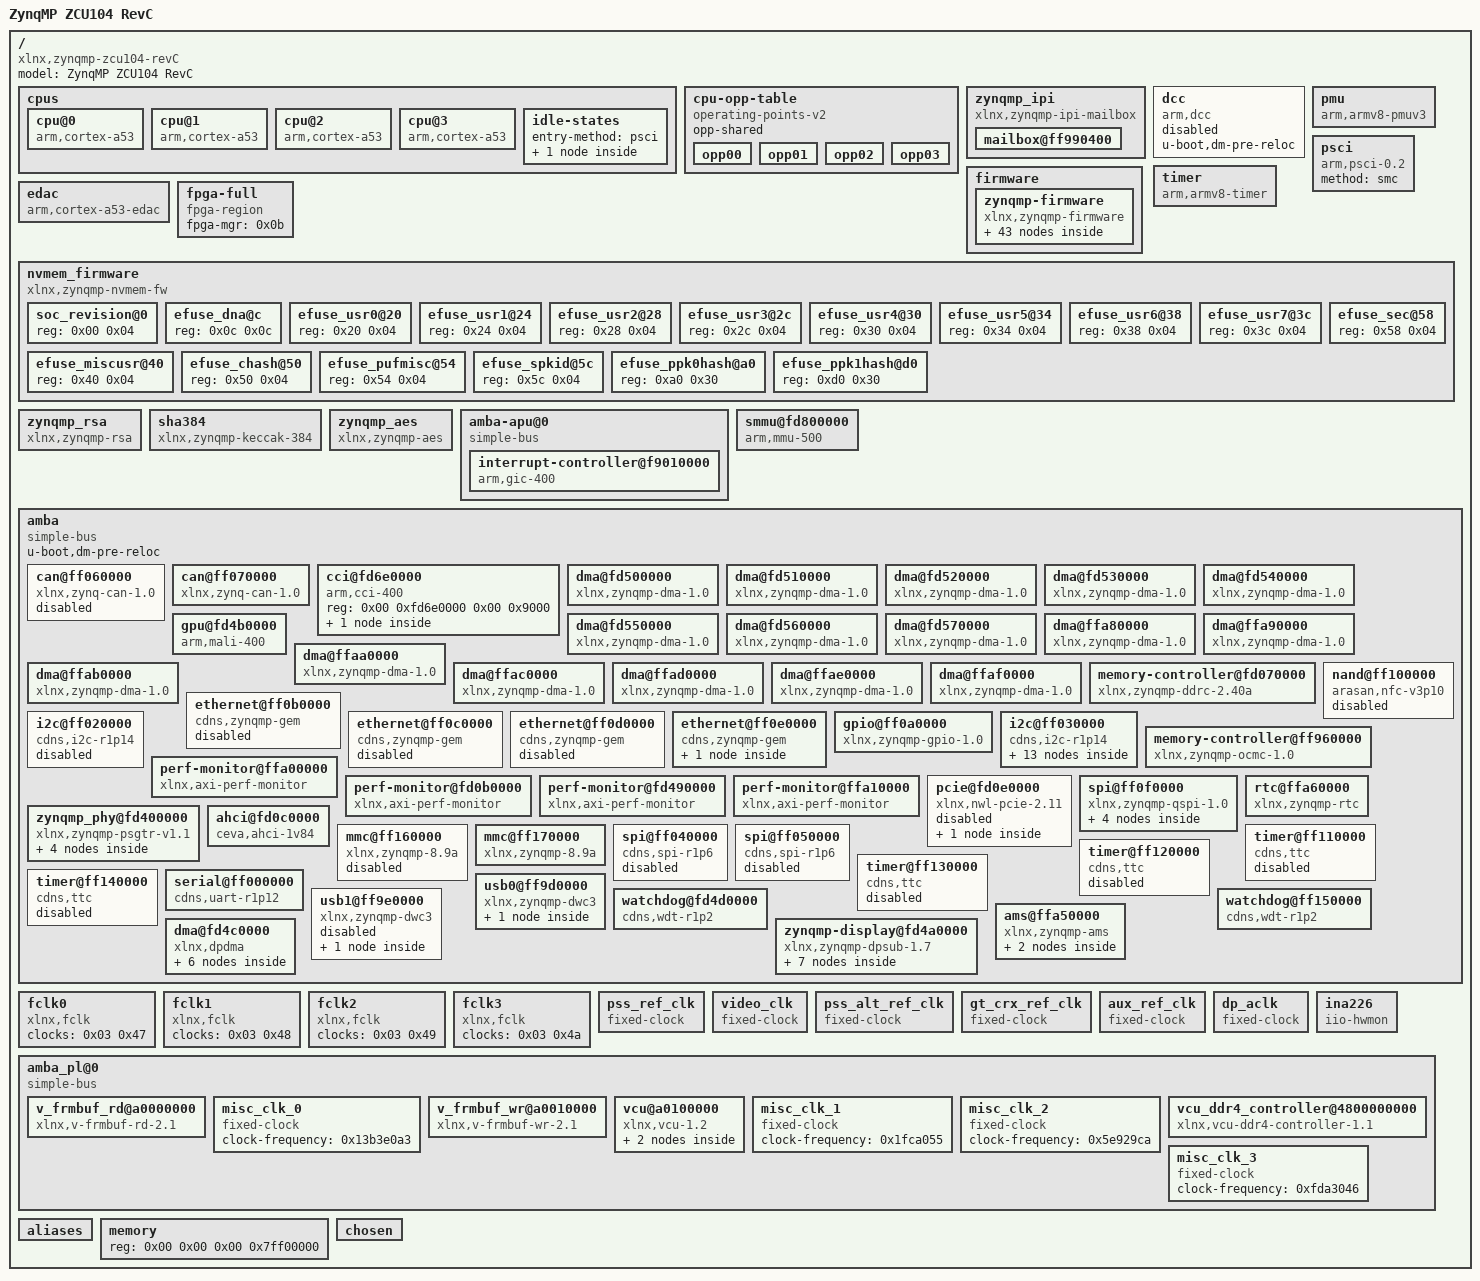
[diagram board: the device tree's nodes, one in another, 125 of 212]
/dts-v1/;

/ {
	compatible = "xlnx,zynqmp-zcu104-revC\0xlnx,zynqmp-zcu104\0xlnx,zynqmp";
	#address-cells = <0x02>;
	#size-cells = <0x02>;
	model = "ZynqMP ZCU104 RevC";

	cpus {
		#address-cells = <0x01>;
		#size-cells = <0x00>;

		cpu@0 {
			compatible = "arm,cortex-a53";
			device_type = "cpu";
			enable-method = "psci";
			operating-points-v2 = <0x01>;
			reg = <0x00>;
			cpu-idle-states = <0x02>;
			clocks = <0x03 0x0a>;
		};

		cpu@1 {
			compatible = "arm,cortex-a53";
			device_type = "cpu";
			enable-method = "psci";
			reg = <0x01>;
			operating-points-v2 = <0x01>;
			cpu-idle-states = <0x02>;
		};

		cpu@2 {
			compatible = "arm,cortex-a53";
			device_type = "cpu";
			enable-method = "psci";
			reg = <0x02>;
			operating-points-v2 = <0x01>;
			cpu-idle-states = <0x02>;
		};

		cpu@3 {
			compatible = "arm,cortex-a53";
			device_type = "cpu";
			enable-method = "psci";
			reg = <0x03>;
			operating-points-v2 = <0x01>;
			cpu-idle-states = <0x02>;
		};

		idle-states {
			entry-method = "psci";

			cpu-sleep-0 {
				compatible = "arm,idle-state";
				arm,psci-suspend-param = <0x40000000>;
				local-timer-stop;
				entry-latency-us = <0x12c>;
				exit-latency-us = <0x258>;
				min-residency-us = <0x2710>;
				phandle = <0x02>;
			};
		};
	};

	cpu-opp-table {
		compatible = "operating-points-v2";
		opp-shared;
		phandle = <0x01>;

		opp00 {
			opp-hz = <0x00 0x47868bf4>;
			opp-microvolt = <0xf4240>;
			clock-latency-ns = <0x7a120>;
		};

		opp01 {
			opp-hz = <0x00 0x23c345fa>;
			opp-microvolt = <0xf4240>;
			clock-latency-ns = <0x7a120>;
		};

		opp02 {
			opp-hz = <0x00 0x17d783fc>;
			opp-microvolt = <0xf4240>;
			clock-latency-ns = <0x7a120>;
		};

		opp03 {
			opp-hz = <0x00 0x11e1a2fd>;
			opp-microvolt = <0xf4240>;
			clock-latency-ns = <0x7a120>;
		};
	};

	zynqmp_ipi {
		u-boot,dm-pre-reloc;
		compatible = "xlnx,zynqmp-ipi-mailbox";
		interrupt-parent = <0x04>;
		interrupts = <0x00 0x23 0x04>;
		xlnx,ipi-id = <0x00>;
		#address-cells = <0x02>;
		#size-cells = <0x02>;
		ranges;

		mailbox@ff990400 {
			u-boot,dm-pre-reloc;
			reg = <0x00 0xff9905c0 0x00 0x20 0x00 0xff9905e0 0x00 0x20 0x00 0xff990e80 0x00 0x20 0x00 0xff990ea0 0x00 0x20>;
			reg-names = "local_request_region\0local_response_region\0remote_request_region\0remote_response_region";
			#mbox-cells = <0x01>;
			xlnx,ipi-id = <0x04>;
			phandle = <0x05>;
		};
	};

	dcc {
		compatible = "arm,dcc";
		status = "disabled";
		u-boot,dm-pre-reloc;
	};

	pmu {
		compatible = "arm,armv8-pmuv3";
		interrupt-parent = <0x04>;
		interrupts = <0x00 0x8f 0x04 0x00 0x90 0x04 0x00 0x91 0x04 0x00 0x92 0x04>;
	};

	psci {
		compatible = "arm,psci-0.2";
		method = "smc";
	};

	firmware {

		zynqmp-firmware {
			compatible = "xlnx,zynqmp-firmware";
			u-boot,dm-pre-reloc;
			method = "smc";
			#power-domain-cells = <0x01>;
			phandle = <0x26>;

			pcap {
				compatible = "xlnx,zynqmp-pcap-fpga";
				clock-names = "ref_clk";
				clocks = <0x03 0x29>;
				phandle = <0x0b>;
			};

			zynqmp-power {
				u-boot,dm-pre-reloc;
				compatible = "xlnx,zynqmp-power";
				interrupt-parent = <0x04>;
				interrupts = <0x00 0x23 0x04>;
				mboxes = <0x05 0x00 0x05 0x01>;
				mbox-names = "tx\0rx";
			};

			reset-controller {
				compatible = "xlnx,zynqmp-reset";
				#reset-cells = <0x01>;
				phandle = <0x31>;
			};

			pinctrl {
				compatible = "xlnx,zynqmp-pinctrl";
				status = "okay";

				can1-default {
					phandle = <0x27>;

					mux {
						function = "can1";
						groups = "can1_6_grp";
					};

					conf {
						groups = "can1_6_grp";
						slew-rate = <0x01>;
						io-standard = <0x01>;
						drive-strength = <0x0c>;
					};

					conf-rx {
						pins = "MIO25";
						bias-high-impedance;
					};

					conf-tx {
						pins = "MIO24";
						bias-disable;
					};
				};

				i2c1-default {
					phandle = <0x2b>;

					mux {
						groups = "i2c1_4_grp";
						function = "i2c1";
					};

					conf {
						groups = "i2c1_4_grp";
						bias-pull-up;
						slew-rate = <0x01>;
						io-standard = <0x01>;
						drive-strength = <0x0c>;
					};
				};

				i2c1-gpio {
					phandle = <0x2c>;

					mux {
						groups = "gpio0_16_grp\0gpio0_17_grp";
						function = "gpio0";
					};

					conf {
						groups = "gpio0_16_grp\0gpio0_17_grp";
						slew-rate = <0x01>;
						io-standard = <0x01>;
						drive-strength = <0x0c>;
					};
				};

				gem3-default {
					phandle = <0x2a>;

					mux {
						function = "ethernet3";
						groups = "ethernet3_0_grp";
					};

					conf {
						groups = "ethernet3_0_grp";
						slew-rate = <0x01>;
						io-standard = <0x01>;
						drive-strength = <0x0c>;
					};

					conf-rx {
						pins = "MIO70\0MIO71\0MIO72\0MIO73\0MIO74\0MIO75";
						bias-high-impedance;
						low-power-disable;
					};

					conf-tx {
						pins = "MIO64\0MIO65\0MIO66\0MIO67\0MIO68\0MIO69";
						bias-disable;
						low-power-enable;
					};

					mux-mdio {
						function = "mdio3";
						groups = "mdio3_0_grp";
					};

					conf-mdio {
						groups = "mdio3_0_grp";
						slew-rate = <0x01>;
						io-standard = <0x01>;
						bias-disable;
					};
				};

				sdhci1-default {
					phandle = <0x33>;

					mux {
						groups = "sdio1_0_grp";
						function = "sdio1";
					};

					conf {
						groups = "sdio1_0_grp";
						slew-rate = <0x01>;
						io-standard = <0x01>;
						bias-disable;
						drive-strength = <0x0c>;
					};

					mux-cd {
						groups = "sdio1_cd_0_grp";
						function = "sdio1_cd";
					};

					conf-cd {
						groups = "sdio1_cd_0_grp";
						bias-high-impedance;
						bias-pull-up;
						slew-rate = <0x01>;
						io-standard = <0x01>;
					};
				};

				uart0-default {
					phandle = <0x34>;

					mux {
						groups = "uart0_4_grp";
						function = "uart0";
					};

					conf {
						groups = "uart0_4_grp";
						slew-rate = <0x01>;
						io-standard = <0x01>;
						drive-strength = <0x0c>;
					};

					conf-rx {
						pins = "MIO18";
						bias-high-impedance;
					};

					conf-tx {
						pins = "MIO19";
						bias-disable;
					};
				};

				uart1-default {
					phandle = <0x35>;

					mux {
						groups = "uart1_5_grp";
						function = "uart1";
					};

					conf {
						groups = "uart1_5_grp";
						slew-rate = <0x01>;
						io-standard = <0x01>;
						drive-strength = <0x0c>;
					};

					conf-rx {
						pins = "MIO21";
						bias-high-impedance;
					};

					conf-tx {
						pins = "MIO20";
						bias-disable;
					};
				};

				usb0-default {
					phandle = <0x36>;

					mux {
						groups = "usb0_0_grp";
						function = "usb0";
					};

					conf {
						groups = "usb0_0_grp";
						slew-rate = <0x01>;
						io-standard = <0x01>;
						drive-strength = <0x0c>;
					};

					conf-rx {
						pins = "MIO52\0MIO53\0MIO55";
						bias-high-impedance;
					};

					conf-tx {
						pins = "MIO54\0MIO56\0MIO57\0MIO58\0MIO59\0MIO60\0MIO61\0MIO62\0MIO63";
						bias-disable;
					};
				};
			};

			clock-controller {
				u-boot,dm-pre-reloc;
				#clock-cells = <0x01>;
				compatible = "xlnx,zynqmp-clk";
				clocks = <0x06 0x07 0x08 0x09 0x0a>;
				clock-names = "pss_ref_clk\0video_clk\0pss_alt_ref_clk\0aux_ref_clk\0gt_crx_ref_clk";
				phandle = <0x03>;
			};
		};
	};

	timer {
		compatible = "arm,armv8-timer";
		interrupt-parent = <0x04>;
		interrupts = <0x01 0x0d 0xf08 0x01 0x0e 0xf08 0x01 0x0b 0xf08 0x01 0x0a 0xf08>;
	};

	edac {
		compatible = "arm,cortex-a53-edac";
	};

	fpga-full {
		compatible = "fpga-region";
		fpga-mgr = <0x0b>;
		#address-cells = <0x02>;
		#size-cells = <0x02>;
		ranges;
	};

	nvmem_firmware {
		compatible = "xlnx,zynqmp-nvmem-fw";
		#address-cells = <0x01>;
		#size-cells = <0x01>;

		soc_revision@0 {
			reg = <0x00 0x04>;
			phandle = <0x30>;
		};

		efuse_dna@c {
			reg = <0x0c 0x0c>;
		};

		efuse_usr0@20 {
			reg = <0x20 0x04>;
		};

		efuse_usr1@24 {
			reg = <0x24 0x04>;
		};

		efuse_usr2@28 {
			reg = <0x28 0x04>;
		};

		efuse_usr3@2c {
			reg = <0x2c 0x04>;
		};

		efuse_usr4@30 {
			reg = <0x30 0x04>;
		};

		efuse_usr5@34 {
			reg = <0x34 0x04>;
		};

		efuse_usr6@38 {
			reg = <0x38 0x04>;
		};

		efuse_usr7@3c {
			reg = <0x3c 0x04>;
		};

		efuse_miscusr@40 {
			reg = <0x40 0x04>;
		};

		efuse_chash@50 {
			reg = <0x50 0x04>;
		};

		efuse_pufmisc@54 {
			reg = <0x54 0x04>;
		};

		efuse_sec@58 {
			reg = <0x58 0x04>;
		};

		efuse_spkid@5c {
			reg = <0x5c 0x04>;
		};

		efuse_ppk0hash@a0 {
			reg = <0xa0 0x30>;
		};

		efuse_ppk1hash@d0 {
			reg = <0xd0 0x30>;
		};
	};

	zynqmp_rsa {
		compatible = "xlnx,zynqmp-rsa";
	};

	sha384 {
		compatible = "xlnx,zynqmp-keccak-384";
	};

	zynqmp_aes {
		compatible = "xlnx,zynqmp-aes";
	};

	amba-apu@0 {
		compatible = "simple-bus";
		#address-cells = <0x02>;
		#size-cells = <0x01>;
		ranges = <0x00 0x00 0x00 0x00 0xffffffff>;

		interrupt-controller@f9010000 {
			compatible = "arm,gic-400";
			#interrupt-cells = <0x03>;
			reg = <0x00 0xf9010000 0x10000 0x00 0xf9020000 0x20000 0x00 0xf9040000 0x20000 0x00 0xf9060000 0x20000>;
			interrupt-controller;
			interrupt-parent = <0x04>;
			interrupts = <0x01 0x09 0xf04>;
			num_cpus = <0x02>;
			num_interrupts = <0x60>;
			phandle = <0x04>;
		};
	};

	smmu@fd800000 {
		compatible = "arm,mmu-500";
		reg = <0x00 0xfd800000 0x00 0x20000>;
		#iommu-cells = <0x01>;
		status = "okay";
		#global-interrupts = <0x01>;
		interrupt-parent = <0x04>;
		interrupts = <0x00 0x9b 0x04 0x00 0x9b 0x04 0x00 0x9b 0x04 0x00 0x9b 0x04 0x00 0x9b 0x04 0x00 0x9b 0x04 0x00 0x9b 0x04 0x00 0x9b 0x04 0x00 0x9b 0x04 0x00 0x9b 0x04 0x00 0x9b 0x04 0x00 0x9b 0x04 0x00 0x9b 0x04 0x00 0x9b 0x04 0x00 0x9b 0x04 0x00 0x9b 0x04 0x00 0x9b 0x04>;
		mmu-masters = <0x0c 0x874 0x0d 0x875 0x0e 0x876 0x0f 0x877 0x10 0x860 0x11 0x861 0x12 0x873 0x13 0x868 0x14 0x869 0x15 0x86a 0x16 0x86b 0x17 0x86c 0x18 0x86d 0x19 0x86e 0x1a 0x86f 0x1b 0x14e8 0x1c 0x14e9 0x1d 0x14ea 0x1e 0x14eb 0x1f 0x14ec 0x20 0x14ed 0x21 0x14ee 0x22 0x14ef 0x23 0x870 0x24 0x871 0x25 0x872>;
		phandle = <0x28>;
	};

	amba {
		compatible = "simple-bus";
		u-boot,dm-pre-reloc;
		#address-cells = <0x02>;
		#size-cells = <0x02>;
		ranges;

		can@ff060000 {
			compatible = "xlnx,zynq-can-1.0";
			status = "disabled";
			clock-names = "can_clk\0pclk";
			reg = <0x00 0xff060000 0x00 0x1000>;
			interrupts = <0x00 0x17 0x04>;
			interrupt-parent = <0x04>;
			tx-fifo-depth = <0x40>;
			rx-fifo-depth = <0x40>;
			power-domains = <0x26 0x2f>;
			clocks = <0x03 0x3f 0x03 0x1f>;
		};

		can@ff070000 {
			compatible = "xlnx,zynq-can-1.0";
			status = "okay";
			clock-names = "can_clk\0pclk";
			reg = <0x00 0xff070000 0x00 0x1000>;
			interrupts = <0x00 0x18 0x04>;
			interrupt-parent = <0x04>;
			tx-fifo-depth = <0x40>;
			rx-fifo-depth = <0x40>;
			power-domains = <0x26 0x30>;
			clocks = <0x03 0x40 0x03 0x1f>;
			pinctrl-names = "default";
			pinctrl-0 = <0x27>;
		};

		cci@fd6e0000 {
			compatible = "arm,cci-400";
			reg = <0x00 0xfd6e0000 0x00 0x9000>;
			ranges = <0x00 0x00 0xfd6e0000 0x10000>;
			#address-cells = <0x01>;
			#size-cells = <0x01>;

			pmu@9000 {
				compatible = "arm,cci-400-pmu,r1";
				reg = <0x9000 0x5000>;
				interrupt-parent = <0x04>;
				interrupts = <0x00 0x7b 0x04 0x00 0x7b 0x04 0x00 0x7b 0x04 0x00 0x7b 0x04 0x00 0x7b 0x04>;
			};
		};

		dma@fd500000 {
			status = "okay";
			compatible = "xlnx,zynqmp-dma-1.0";
			reg = <0x00 0xfd500000 0x00 0x1000>;
			interrupt-parent = <0x04>;
			interrupts = <0x00 0x7c 0x04>;
			clock-names = "clk_main\0clk_apb";
			xlnx,bus-width = <0x80>;
			#stream-id-cells = <0x01>;
			iommus = <0x28 0x14e8>;
			power-domains = <0x26 0x2a>;
			clocks = <0x03 0x13 0x03 0x1f>;
			phandle = <0x1b>;
		};

		dma@fd510000 {
			status = "okay";
			compatible = "xlnx,zynqmp-dma-1.0";
			reg = <0x00 0xfd510000 0x00 0x1000>;
			interrupt-parent = <0x04>;
			interrupts = <0x00 0x7d 0x04>;
			clock-names = "clk_main\0clk_apb";
			xlnx,bus-width = <0x80>;
			#stream-id-cells = <0x01>;
			iommus = <0x28 0x14e9>;
			power-domains = <0x26 0x2a>;
			clocks = <0x03 0x13 0x03 0x1f>;
			phandle = <0x1c>;
		};

		dma@fd520000 {
			status = "okay";
			compatible = "xlnx,zynqmp-dma-1.0";
			reg = <0x00 0xfd520000 0x00 0x1000>;
			interrupt-parent = <0x04>;
			interrupts = <0x00 0x7e 0x04>;
			clock-names = "clk_main\0clk_apb";
			xlnx,bus-width = <0x80>;
			#stream-id-cells = <0x01>;
			iommus = <0x28 0x14ea>;
			power-domains = <0x26 0x2a>;
			clocks = <0x03 0x13 0x03 0x1f>;
			phandle = <0x1d>;
		};

		dma@fd530000 {
			status = "okay";
			compatible = "xlnx,zynqmp-dma-1.0";
			reg = <0x00 0xfd530000 0x00 0x1000>;
			interrupt-parent = <0x04>;
			interrupts = <0x00 0x7f 0x04>;
			clock-names = "clk_main\0clk_apb";
			xlnx,bus-width = <0x80>;
			#stream-id-cells = <0x01>;
			iommus = <0x28 0x14eb>;
			power-domains = <0x26 0x2a>;
			clocks = <0x03 0x13 0x03 0x1f>;
			phandle = <0x1e>;
		};

		dma@fd540000 {
			status = "okay";
			compatible = "xlnx,zynqmp-dma-1.0";
			reg = <0x00 0xfd540000 0x00 0x1000>;
			interrupt-parent = <0x04>;
			interrupts = <0x00 0x80 0x04>;
			clock-names = "clk_main\0clk_apb";
			xlnx,bus-width = <0x80>;
			#stream-id-cells = <0x01>;
			iommus = <0x28 0x14ec>;
			power-domains = <0x26 0x2a>;
			clocks = <0x03 0x13 0x03 0x1f>;
			phandle = <0x1f>;
		};

		dma@fd550000 {
			status = "okay";
			compatible = "xlnx,zynqmp-dma-1.0";
			reg = <0x00 0xfd550000 0x00 0x1000>;
			interrupt-parent = <0x04>;
			interrupts = <0x00 0x81 0x04>;
			clock-names = "clk_main\0clk_apb";
			xlnx,bus-width = <0x80>;
			#stream-id-cells = <0x01>;
			iommus = <0x28 0x14ed>;
			power-domains = <0x26 0x2a>;
			clocks = <0x03 0x13 0x03 0x1f>;
			phandle = <0x20>;
		};

		dma@fd560000 {
			status = "okay";
			compatible = "xlnx,zynqmp-dma-1.0";
			reg = <0x00 0xfd560000 0x00 0x1000>;
			interrupt-parent = <0x04>;
			interrupts = <0x00 0x82 0x04>;
			clock-names = "clk_main\0clk_apb";
			xlnx,bus-width = <0x80>;
			#stream-id-cells = <0x01>;
			iommus = <0x28 0x14ee>;
			power-domains = <0x26 0x2a>;
			clocks = <0x03 0x13 0x03 0x1f>;
			phandle = <0x21>;
		};

		dma@fd570000 {
			status = "okay";
			compatible = "xlnx,zynqmp-dma-1.0";
			reg = <0x00 0xfd570000 0x00 0x1000>;
			interrupt-parent = <0x04>;
			interrupts = <0x00 0x83 0x04>;
			clock-names = "clk_main\0clk_apb";
			xlnx,bus-width = <0x80>;
			#stream-id-cells = <0x01>;
			iommus = <0x28 0x14ef>;
			power-domains = <0x26 0x2a>;
			clocks = <0x03 0x13 0x03 0x1f>;
			phandle = <0x22>;
		};

		gpu@fd4b0000 {
			status = "okay";
			compatible = "arm,mali-400\0arm,mali-utgard";
			reg = <0x00 0xfd4b0000 0x00 0x10000>;
			interrupt-parent = <0x04>;
			interrupts = <0x00 0x84 0x04 0x00 0x84 0x04 0x00 0x84 0x04 0x00 0x84 0x04 0x00 0x84 0x04 0x00 0x84 0x04>;
			interrupt-names = "IRQGP\0IRQGPMMU\0IRQPP0\0IRQPPMMU0\0IRQPP1\0IRQPPMMU1";
			clock-names = "gpu\0gpu_pp0\0gpu_pp1";
			power-domains = <0x26 0x3a>;
			clocks = <0x03 0x18 0x03 0x19 0x03 0x1a>;
			xlnx,tz-nonsecure = <0x01>;
		};

		dma@ffa80000 {
			status = "okay";
			compatible = "xlnx,zynqmp-dma-1.0";
			reg = <0x00 0xffa80000 0x00 0x1000>;
			interrupt-parent = <0x04>;
			interrupts = <0x00 0x4d 0x04>;
			clock-names = "clk_main\0clk_apb";
			xlnx,bus-width = <0x40>;
			#stream-id-cells = <0x01>;
			power-domains = <0x26 0x2b>;
			clocks = <0x03 0x44 0x03 0x1f>;
			phandle = <0x13>;
		};

		dma@ffa90000 {
			status = "okay";
			compatible = "xlnx,zynqmp-dma-1.0";
			reg = <0x00 0xffa90000 0x00 0x1000>;
			interrupt-parent = <0x04>;
			interrupts = <0x00 0x4e 0x04>;
			clock-names = "clk_main\0clk_apb";
			xlnx,bus-width = <0x40>;
			#stream-id-cells = <0x01>;
			power-domains = <0x26 0x2b>;
			clocks = <0x03 0x44 0x03 0x1f>;
			phandle = <0x14>;
		};

		dma@ffaa0000 {
			status = "okay";
			compatible = "xlnx,zynqmp-dma-1.0";
			reg = <0x00 0xffaa0000 0x00 0x1000>;
			interrupt-parent = <0x04>;
			interrupts = <0x00 0x4f 0x04>;
			clock-names = "clk_main\0clk_apb";
			xlnx,bus-width = <0x40>;
			#stream-id-cells = <0x01>;
			power-domains = <0x26 0x2b>;
			clocks = <0x03 0x44 0x03 0x1f>;
			phandle = <0x15>;
		};

		dma@ffab0000 {
			status = "okay";
			compatible = "xlnx,zynqmp-dma-1.0";
			reg = <0x00 0xffab0000 0x00 0x1000>;
			interrupt-parent = <0x04>;
			interrupts = <0x00 0x50 0x04>;
			clock-names = "clk_main\0clk_apb";
			xlnx,bus-width = <0x40>;
			#stream-id-cells = <0x01>;
			power-domains = <0x26 0x2b>;
			clocks = <0x03 0x44 0x03 0x1f>;
			phandle = <0x16>;
		};

		dma@ffac0000 {
			status = "okay";
			compatible = "xlnx,zynqmp-dma-1.0";
			reg = <0x00 0xffac0000 0x00 0x1000>;
			interrupt-parent = <0x04>;
			interrupts = <0x00 0x51 0x04>;
			clock-names = "clk_main\0clk_apb";
			xlnx,bus-width = <0x40>;
			#stream-id-cells = <0x01>;
			power-domains = <0x26 0x2b>;
			clocks = <0x03 0x44 0x03 0x1f>;
			phandle = <0x17>;
		};

		dma@ffad0000 {
			status = "okay";
			compatible = "xlnx,zynqmp-dma-1.0";
			reg = <0x00 0xffad0000 0x00 0x1000>;
			interrupt-parent = <0x04>;
			interrupts = <0x00 0x52 0x04>;
			clock-names = "clk_main\0clk_apb";
			xlnx,bus-width = <0x40>;
			#stream-id-cells = <0x01>;
			power-domains = <0x26 0x2b>;
			clocks = <0x03 0x44 0x03 0x1f>;
			phandle = <0x18>;
		};

		dma@ffae0000 {
			status = "okay";
			compatible = "xlnx,zynqmp-dma-1.0";
			reg = <0x00 0xffae0000 0x00 0x1000>;
			interrupt-parent = <0x04>;
			interrupts = <0x00 0x53 0x04>;
			clock-names = "clk_main\0clk_apb";
			xlnx,bus-width = <0x40>;
			#stream-id-cells = <0x01>;
			power-domains = <0x26 0x2b>;
			clocks = <0x03 0x44 0x03 0x1f>;
			phandle = <0x19>;
		};

		dma@ffaf0000 {
			status = "okay";
			compatible = "xlnx,zynqmp-dma-1.0";
			reg = <0x00 0xffaf0000 0x00 0x1000>;
			interrupt-parent = <0x04>;
			interrupts = <0x00 0x54 0x04>;
			clock-names = "clk_main\0clk_apb";
			xlnx,bus-width = <0x40>;
			#stream-id-cells = <0x01>;
			power-domains = <0x26 0x2b>;
			clocks = <0x03 0x44 0x03 0x1f>;
			phandle = <0x1a>;
		};

		memory-controller@fd070000 {
			compatible = "xlnx,zynqmp-ddrc-2.40a";
			reg = <0x00 0xfd070000 0x00 0x30000>;
			interrupt-parent = <0x04>;
			interrupts = <0x00 0x70 0x04>;
		};

		nand@ff100000 {
			compatible = "arasan,nfc-v3p10";
			status = "disabled";
			reg = <0x00 0xff100000 0x00 0x1000>;
			clock-names = "clk_sys\0clk_flash";
			interrupt-parent = <0x04>;
			interrupts = <0x00 0x0e 0x04>;
			#address-cells = <0x01>;
			#size-cells = <0x00>;
			#stream-id-cells = <0x01>;
			iommus = <0x28 0x872>;
			power-domains = <0x26 0x2c>;
			clocks = <0x03 0x3c 0x03 0x1f>;
			phandle = <0x25>;
		};

		ethernet@ff0b0000 {
			compatible = "cdns,zynqmp-gem\0cdns,gem";
			status = "disabled";
			interrupt-parent = <0x04>;
			interrupts = <0x00 0x39 0x04 0x00 0x39 0x04>;
			reg = <0x00 0xff0b0000 0x00 0x1000>;
			clock-names = "pclk\0hclk\0tx_clk\0rx_clk\0tsu_clk";
			#address-cells = <0x01>;
			#size-cells = <0x00>;
			#stream-id-cells = <0x01>;
			iommus = <0x28 0x874>;
			power-domains = <0x26 0x1d>;
			clocks = <0x03 0x1f 0x03 0x68 0x03 0x2d 0x03 0x31 0x03 0x2c>;
			phandle = <0x0c>;
		};

		ethernet@ff0c0000 {
			compatible = "cdns,zynqmp-gem\0cdns,gem";
			status = "disabled";
			interrupt-parent = <0x04>;
			interrupts = <0x00 0x3b 0x04 0x00 0x3b 0x04>;
			reg = <0x00 0xff0c0000 0x00 0x1000>;
			clock-names = "pclk\0hclk\0tx_clk\0rx_clk\0tsu_clk";
			#address-cells = <0x01>;
			#size-cells = <0x00>;
			#stream-id-cells = <0x01>;
			iommus = <0x28 0x875>;
			power-domains = <0x26 0x1e>;
			clocks = <0x03 0x1f 0x03 0x69 0x03 0x2e 0x03 0x32 0x03 0x2c>;
			phandle = <0x0d>;
		};

		ethernet@ff0d0000 {
			compatible = "cdns,zynqmp-gem\0cdns,gem";
			status = "disabled";
			interrupt-parent = <0x04>;
			interrupts = <0x00 0x3d 0x04 0x00 0x3d 0x04>;
			reg = <0x00 0xff0d0000 0x00 0x1000>;
			clock-names = "pclk\0hclk\0tx_clk\0rx_clk\0tsu_clk";
			#address-cells = <0x01>;
			#size-cells = <0x00>;
			#stream-id-cells = <0x01>;
			iommus = <0x28 0x876>;
			power-domains = <0x26 0x1f>;
			clocks = <0x03 0x1f 0x03 0x6a 0x03 0x2f 0x03 0x33 0x03 0x2c>;
			phandle = <0x0e>;
		};

		ethernet@ff0e0000 {
			compatible = "cdns,zynqmp-gem\0cdns,gem";
			status = "okay";
			interrupt-parent = <0x04>;
			interrupts = <0x00 0x3f 0x04 0x00 0x3f 0x04>;
			reg = <0x00 0xff0e0000 0x00 0x1000>;
			clock-names = "pclk\0hclk\0tx_clk\0rx_clk\0tsu_clk";
			#address-cells = <0x01>;
			#size-cells = <0x00>;
			#stream-id-cells = <0x01>;
			iommus = <0x28 0x877>;
			power-domains = <0x26 0x20>;
			clocks = <0x03 0x1f 0x03 0x6b 0x03 0x30 0x03 0x34 0x03 0x2c>;
			phy-handle = <0x29>;
			pinctrl-names = "default";
			pinctrl-0 = <0x2a>;
			phy-mode = "rgmii-id";
			xlnx,ptp-enet-clock = <0x00>;
			local-mac-address = [00 0a 35 00 22 01];
			phandle = <0x0f>;

			ethernet-phy@c {
				reg = <0x0c>;
				ti,rx-internal-delay = <0x08>;
				ti,tx-internal-delay = <0x0a>;
				ti,fifo-depth = <0x01>;
				ti,dp83867-rxctrl-strap-quirk;
				phandle = <0x29>;
			};
		};

		gpio@ff0a0000 {
			compatible = "xlnx,zynqmp-gpio-1.0";
			status = "okay";
			#gpio-cells = <0x02>;
			gpio-controller;
			interrupt-parent = <0x04>;
			interrupts = <0x00 0x10 0x04>;
			interrupt-controller;
			#interrupt-cells = <0x02>;
			reg = <0x00 0xff0a0000 0x00 0x1000>;
			power-domains = <0x26 0x2e>;
			clocks = <0x03 0x1f>;
			emio-gpio-width = <0x20>;
			gpio-mask-high = <0x00>;
			gpio-mask-low = <0x5600>;
			phandle = <0x2d>;
		};

		i2c@ff020000 {
			compatible = "cdns,i2c-r1p14\0cdns,i2c-r1p10";
			status = "disabled";
			interrupt-parent = <0x04>;
			interrupts = <0x00 0x11 0x04>;
			reg = <0x00 0xff020000 0x00 0x1000>;
			#address-cells = <0x01>;
			#size-cells = <0x00>;
			power-domains = <0x26 0x25>;
			clocks = <0x03 0x3d>;
		};

		i2c@ff030000 {
			compatible = "cdns,i2c-r1p14\0cdns,i2c-r1p10";
			status = "okay";
			interrupt-parent = <0x04>;
			interrupts = <0x00 0x12 0x04>;
			reg = <0x00 0xff030000 0x00 0x1000>;
			#address-cells = <0x01>;
			#size-cells = <0x00>;
			power-domains = <0x26 0x26>;
			clocks = <0x03 0x3e>;
			pinctrl-names = "default\0gpio";
			pinctrl-0 = <0x2b>;
			pinctrl-1 = <0x2c>;
			scl-gpios = <0x2d 0x10 0x00>;
			sda-gpios = <0x2d 0x11 0x00>;
			clock-frequency = <0x61a80>;

			gpio@20 {
				compatible = "ti,tca6416";
				reg = <0x20>;
				gpio-controller;
				#gpio-cells = <0x02>;
			};

			i2c-mux@74 {
				compatible = "nxp,pca9548";
				#address-cells = <0x01>;
				#size-cells = <0x00>;
				reg = <0x74>;

				i2c@0 {
					#address-cells = <0x01>;
					#size-cells = <0x00>;
					reg = <0x00>;

					eeprom@54 {
						compatible = "atmel,24c08";
						reg = <0x54>;
						#address-cells = <0x01>;
						#size-cells = <0x01>;
					};
				};

				i2c@1 {
					#address-cells = <0x01>;
					#size-cells = <0x00>;
					reg = <0x01>;

					clock-generator@6c {
						compatible = "idt,8t49n287";
						reg = <0x6c>;
					};
				};

				i2c@2 {
					#address-cells = <0x01>;
					#size-cells = <0x00>;
					reg = <0x02>;

					irps5401@43 {
						compatible = "infineon,irps5401";
						reg = <0x43>;
					};

					irps5401@44 {
						compatible = "infineon,irps5401";
						reg = <0x44>;
					};
				};

				i2c@3 {
					#address-cells = <0x01>;
					#size-cells = <0x00>;
					reg = <0x03>;

					ina226@40 {
						compatible = "ti,ina226";
						#io-channel-cells = <0x01>;
						reg = <0x40>;
						shunt-resistor = <0x1388>;
						phandle = <0x3f>;
					};
				};

				i2c@5 {
					#address-cells = <0x01>;
					#size-cells = <0x00>;
					reg = <0x05>;
				};

				i2c@7 {
					#address-cells = <0x01>;
					#size-cells = <0x00>;
					reg = <0x07>;
				};
			};
		};

		memory-controller@ff960000 {
			compatible = "xlnx,zynqmp-ocmc-1.0";
			reg = <0x00 0xff960000 0x00 0x1000>;
			interrupt-parent = <0x04>;
			interrupts = <0x00 0x0a 0x04>;
		};

		perf-monitor@ffa00000 {
			compatible = "xlnx,axi-perf-monitor";
			reg = <0x00 0xffa00000 0x00 0x10000>;
			interrupts = <0x00 0x19 0x04>;
			interrupt-parent = <0x04>;
			xlnx,enable-profile = <0x00>;
			xlnx,enable-trace = <0x00>;
			xlnx,num-monitor-slots = <0x01>;
			xlnx,enable-event-count = <0x01>;
			xlnx,enable-event-log = <0x01>;
			xlnx,have-sampled-metric-cnt = <0x01>;
			xlnx,num-of-counters = <0x08>;
			xlnx,metric-count-width = <0x20>;
			xlnx,metrics-sample-count-width = <0x20>;
			xlnx,global-count-width = <0x20>;
			xlnx,metric-count-scale = <0x01>;
			clocks = <0x03 0x1f>;
		};

		perf-monitor@fd0b0000 {
			compatible = "xlnx,axi-perf-monitor";
			reg = <0x00 0xfd0b0000 0x00 0x10000>;
			interrupts = <0x00 0x7b 0x04>;
			interrupt-parent = <0x04>;
			xlnx,enable-profile = <0x00>;
			xlnx,enable-trace = <0x00>;
			xlnx,num-monitor-slots = <0x06>;
			xlnx,enable-event-count = <0x01>;
			xlnx,enable-event-log = <0x00>;
			xlnx,have-sampled-metric-cnt = <0x01>;
			xlnx,num-of-counters = <0x0a>;
			xlnx,metric-count-width = <0x20>;
			xlnx,metrics-sample-count-width = <0x20>;
			xlnx,global-count-width = <0x20>;
			xlnx,metric-count-scale = <0x01>;
			clocks = <0x03 0x1c>;
		};

		perf-monitor@fd490000 {
			compatible = "xlnx,axi-perf-monitor";
			reg = <0x00 0xfd490000 0x00 0x10000>;
			interrupts = <0x00 0x7b 0x04>;
			interrupt-parent = <0x04>;
			xlnx,enable-profile = <0x00>;
			xlnx,enable-trace = <0x00>;
			xlnx,num-monitor-slots = <0x01>;
			xlnx,enable-event-count = <0x01>;
			xlnx,enable-event-log = <0x00>;
			xlnx,have-sampled-metric-cnt = <0x01>;
			xlnx,num-of-counters = <0x08>;
			xlnx,metric-count-width = <0x20>;
			xlnx,metrics-sample-count-width = <0x20>;
			xlnx,global-count-width = <0x20>;
			xlnx,metric-count-scale = <0x01>;
			clocks = <0x03 0x1c>;
		};

		perf-monitor@ffa10000 {
			compatible = "xlnx,axi-perf-monitor";
			reg = <0x00 0xffa10000 0x00 0x10000>;
			interrupts = <0x00 0x19 0x04>;
			interrupt-parent = <0x04>;
			xlnx,enable-profile = <0x00>;
			xlnx,enable-trace = <0x00>;
			xlnx,num-monitor-slots = <0x01>;
			xlnx,enable-event-count = <0x01>;
			xlnx,enable-event-log = <0x01>;
			xlnx,have-sampled-metric-cnt = <0x01>;
			xlnx,num-of-counters = <0x08>;
			xlnx,metric-count-width = <0x20>;
			xlnx,metrics-sample-count-width = <0x20>;
			xlnx,global-count-width = <0x20>;
			xlnx,metric-count-scale = <0x01>;
			clocks = <0x03 0x1f>;
		};

		pcie@fd0e0000 {
			compatible = "xlnx,nwl-pcie-2.11";
			status = "disabled";
			#address-cells = <0x03>;
			#size-cells = <0x02>;
			#interrupt-cells = <0x01>;
			msi-controller;
			device_type = "pci";
			interrupt-parent = <0x04>;
			interrupts = <0x00 0x76 0x04 0x00 0x75 0x04 0x00 0x74 0x04 0x00 0x73 0x04 0x00 0x72 0x04>;
			interrupt-names = "misc\0dummy\0intx\0msi1\0msi0";
			msi-parent = <0x2e>;
			reg = <0x00 0xfd0e0000 0x00 0x1000 0x00 0xfd480000 0x00 0x1000 0x80 0x00 0x00 0x1000000>;
			reg-names = "breg\0pcireg\0cfg";
			ranges = <0x2000000 0x00 0xe0000000 0x00 0xe0000000 0x00 0x10000000 0x43000000 0x06 0x00 0x06 0x00 0x02 0x00>;
			interrupt-map-mask = <0x00 0x00 0x00 0x07>;
			bus-range = <0x00 0xff>;
			interrupt-map = <0x00 0x00 0x00 0x01 0x2f 0x01 0x00 0x00 0x00 0x02 0x2f 0x02 0x00 0x00 0x00 0x03 0x2f 0x03 0x00 0x00 0x00 0x04 0x2f 0x04>;
			power-domains = <0x26 0x3b>;
			clocks = <0x03 0x17>;
			phandle = <0x2e>;

			legacy-interrupt-controller {
				interrupt-controller;
				#address-cells = <0x00>;
				#interrupt-cells = <0x01>;
				phandle = <0x2f>;
			};
		};

		spi@ff0f0000 {
			u-boot,dm-pre-reloc;
			compatible = "xlnx,zynqmp-qspi-1.0";
			status = "okay";
			clock-names = "ref_clk\0pclk";
			interrupts = <0x00 0x0f 0x04>;
			interrupt-parent = <0x04>;
			num-cs = <0x01>;
			reg = <0x00 0xff0f0000 0x00 0x1000 0x00 0xc0000000 0x00 0x8000000>;
			#address-cells = <0x01>;
			#size-cells = <0x00>;
			#stream-id-cells = <0x01>;
			iommus = <0x28 0x873>;
			power-domains = <0x26 0x2d>;
			clocks = <0x03 0x35 0x03 0x1f>;
			is-dual = <0x00>;
			spi-rx-bus-width = <0x04>;
			spi-tx-bus-width = <0x04>;
			phandle = <0x12>;

			flash@0 {
				compatible = "m25p80\0jedec,spi-nor";
				#address-cells = <0x01>;
				#size-cells = <0x01>;
				reg = <0x00>;
				spi-tx-bus-width = <0x01>;
				spi-rx-bus-width = <0x04>;
				spi-max-frequency = <0x66ff300>;

				partition@0 {
					label = "boot";
					reg = <0x00 0x1e00000>;
				};

				partition@1 {
					label = "bootenv";
					reg = <0x1e00000 0x40000>;
				};

				partition@2 {
					label = "kernel";
					reg = <0x1e40000 0x21c0000>;
				};
			};
		};

		rtc@ffa60000 {
			compatible = "xlnx,zynqmp-rtc";
			status = "okay";
			reg = <0x00 0xffa60000 0x00 0x100>;
			interrupt-parent = <0x04>;
			interrupts = <0x00 0x1a 0x04 0x00 0x1b 0x04>;
			interrupt-names = "alarm\0sec";
			calibration = <0x8000>;
		};

		zynqmp_phy@fd400000 {
			compatible = "xlnx,zynqmp-psgtr-v1.1";
			status = "okay";
			reg = <0x00 0xfd400000 0x00 0x40000 0x00 0xfd3d0000 0x00 0x1000>;
			reg-names = "serdes\0siou";
			nvmem-cells = <0x30>;
			nvmem-cell-names = "soc_revision";
			resets = <0x31 0x10 0x31 0x3b 0x31 0x3c 0x31 0x3d 0x31 0x3e 0x31 0x3f 0x31 0x40 0x31 0x03 0x31 0x1d 0x31 0x1e 0x31 0x1f 0x31 0x20>;
			reset-names = "sata_rst\0usb0_crst\0usb1_crst\0usb0_hibrst\0usb1_hibrst\0usb0_apbrst\0usb1_apbrst\0dp_rst\0gem0_rst\0gem1_rst\0gem2_rst\0gem3_rst";

			lane0 {
				#phy-cells = <0x04>;
				phandle = <0x3a>;
			};

			lane1 {
				#phy-cells = <0x04>;
				phandle = <0x39>;
			};

			lane2 {
				#phy-cells = <0x04>;
				phandle = <0x37>;
			};

			lane3 {
				#phy-cells = <0x04>;
				phandle = <0x32>;
			};
		};

		ahci@fd0c0000 {
			compatible = "ceva,ahci-1v84";
			status = "okay";
			reg = <0x00 0xfd0c0000 0x00 0x2000>;
			interrupt-parent = <0x04>;
			interrupts = <0x00 0x85 0x04>;
			power-domains = <0x26 0x1c>;
			#stream-id-cells = <0x04>;
			clocks = <0x03 0x16>;
			ceva,p0-cominit-params = <0x18401828>;
			ceva,p0-comwake-params = <0x614080e>;
			ceva,p0-burst-params = <0x13084a06>;
			ceva,p0-retry-params = <0x96a43ffc>;
			ceva,p1-cominit-params = <0x18401828>;
			ceva,p1-comwake-params = <0x614080e>;
			ceva,p1-burst-params = <0x13084a06>;
			ceva,p1-retry-params = <0x96a43ffc>;
			phy-names = "sata-phy";
			phys = <0x32 0x01 0x01 0x01 0x7735940>;
			xlnx,tz-nonsecure-sata0 = <0x00>;
			xlnx,tz-nonsecure-sata1 = <0x00>;
		};

		mmc@ff160000 {
			u-boot,dm-pre-reloc;
			compatible = "xlnx,zynqmp-8.9a\0arasan,sdhci-8.9a";
			status = "disabled";
			interrupt-parent = <0x04>;
			interrupts = <0x00 0x30 0x04>;
			reg = <0x00 0xff160000 0x00 0x1000>;
			clock-names = "clk_xin\0clk_ahb";
			xlnx,device_id = <0x00>;
			#stream-id-cells = <0x01>;
			iommus = <0x28 0x870>;
			power-domains = <0x26 0x27>;
			nvmem-cells = <0x30>;
			nvmem-cell-names = "soc_revision";
			#clock-cells = <0x01>;
			clock-output-names = "clk_out_sd0\0clk_in_sd0";
			clocks = <0x03 0x36 0x03 0x1f>;
			phandle = <0x23>;
		};

		mmc@ff170000 {
			u-boot,dm-pre-reloc;
			compatible = "xlnx,zynqmp-8.9a\0arasan,sdhci-8.9a";
			status = "okay";
			interrupt-parent = <0x04>;
			interrupts = <0x00 0x31 0x04>;
			reg = <0x00 0xff170000 0x00 0x1000>;
			clock-names = "clk_xin\0clk_ahb";
			xlnx,device_id = <0x01>;
			#stream-id-cells = <0x01>;
			iommus = <0x28 0x871>;
			power-domains = <0x26 0x28>;
			nvmem-cells = <0x30>;
			nvmem-cell-names = "soc_revision";
			#clock-cells = <0x01>;
			clock-output-names = "clk_out_sd1\0clk_in_sd1";
			clocks = <0x03 0x37 0x03 0x1f>;	
			no-1-8-v;
			pinctrl-names = "default";
			pinctrl-0 = <0x33>;
			xlnx,mio_bank = <0x01>;
			disable-wp;
			clock-frequency = <0xb2d05e0>;
			phandle = <0x24>;
		};

		spi@ff040000 {
			compatible = "cdns,spi-r1p6";
			status = "disabled";
			interrupt-parent = <0x04>;
			interrupts = <0x00 0x13 0x04>;
			reg = <0x00 0xff040000 0x00 0x1000>;
			clock-names = "ref_clk\0pclk";
			#address-cells = <0x01>;
			#size-cells = <0x00>;
			power-domains = <0x26 0x23>;
			clocks = <0x03 0x3a 0x03 0x1f>;
		};

		spi@ff050000 {
			compatible = "cdns,spi-r1p6";
			status = "disabled";
			interrupt-parent = <0x04>;
			interrupts = <0x00 0x14 0x04>;
			reg = <0x00 0xff050000 0x00 0x1000>;
			clock-names = "ref_clk\0pclk";
			#address-cells = <0x01>;
			#size-cells = <0x00>;
			power-domains = <0x26 0x24>;
			clocks = <0x03 0x3b 0x03 0x1f>;
		};

		timer@ff110000 {
			compatible = "cdns,ttc";
			status = "disabled";
			interrupt-parent = <0x04>;
			interrupts = <0x00 0x24 0x04 0x00 0x25 0x04 0x00 0x26 0x04>;
			reg = <0x00 0xff110000 0x00 0x1000>;
			timer-width = <0x20>;
			power-domains = <0x26 0x18>;
			clocks = <0x03 0x1f>;
		};

		timer@ff120000 {
			compatible = "cdns,ttc";
			status = "disabled";
			interrupt-parent = <0x04>;
			interrupts = <0x00 0x27 0x04 0x00 0x28 0x04 0x00 0x29 0x04>;
			reg = <0x00 0xff120000 0x00 0x1000>;
			timer-width = <0x20>;
			power-domains = <0x26 0x19>;
			clocks = <0x03 0x1f>;
		};

		timer@ff130000 {
			compatible = "cdns,ttc";
			status = "disabled";
			interrupt-parent = <0x04>;
			interrupts = <0x00 0x2a 0x04 0x00 0x2b 0x04 0x00 0x2c 0x04>;
			reg = <0x00 0xff130000 0x00 0x1000>;
			timer-width = <0x20>;
			power-domains = <0x26 0x1a>;
			clocks = <0x03 0x1f>;
		};

		timer@ff140000 {
			compatible = "cdns,ttc";
			status = "disabled";
			interrupt-parent = <0x04>;
			interrupts = <0x00 0x2d 0x04 0x00 0x2e 0x04 0x00 0x2f 0x04>;
			reg = <0x00 0xff140000 0x00 0x1000>;
			timer-width = <0x20>;
			power-domains = <0x26 0x1b>;
			clocks = <0x03 0x1f>;
		};

		serial@ff000000 {
			u-boot,dm-pre-reloc;
			compatible = "cdns,uart-r1p12\0xlnx,xuartps";
			status = "okay";
			interrupt-parent = <0x04>;
			interrupts = <0x00 0x15 0x04>;
			reg = <0x00 0xff000000 0x00 0x1000>;
			clock-names = "uart_clk\0pclk";
			power-domains = <0x26 0x21>;
			clocks = <0x03 0x38 0x03 0x1f>;
			pinctrl-names = "default";
			pinctrl-0 = <0x34>;
			cts-override;
			device_type = "serial";
			port-number = <0x00>;
		};

		// serial@ff010000 {
		// 	u-boot,dm-pre-reloc;
		// 	compatible = "cdns,uart-r1p12\0xlnx,xuartps";
		// 	status = "okay";
		// 	interrupt-parent = <0x04>;
		// 	interrupts = <0x00 0x16 0x04>;
		// 	reg = <0x00 0xff010000 0x00 0x1000>;
		// 	clock-names = "uart_clk\0pclk";
		// 	power-domains = <0x26 0x22>;
		// 	clocks = <0x03 0x39 0x03 0x1f>;
		// 	pinctrl-names = "default";
		// 	pinctrl-0 = <0x35>;
		// 	cts-override;
		// 	device_type = "serial";
		// 	port-number = <0x01>;
		// };

		usb0@ff9d0000 {
			#address-cells = <0x02>;
			#size-cells = <0x02>;
			status = "okay";
			compatible = "xlnx,zynqmp-dwc3";
			reg = <0x00 0xff9d0000 0x00 0x100>;
			clock-names = "bus_clk\0ref_clk";
			power-domains = <0x26 0x16>;
			ranges;
			nvmem-cells = <0x30>;
			nvmem-cell-names = "soc_revision";
			clocks = <0x03 0x20 0x03 0x22>;
			pinctrl-names = "default";
			pinctrl-0 = <0x36>;
			xlnx,tz-nonsecure = <0x01>;
			xlnx,usb-polarity = <0x00>;
			xlnx,usb-reset-mode = <0x00>;

			dwc3@fe200000 {
				compatible = "snps,dwc3";
				status = "okay";
				reg = <0x00 0xfe200000 0x00 0x40000>;
				interrupt-parent = <0x04>;
				interrupt-names = "dwc_usb3\0otg\0hiber";
				interrupts = <0x00 0x41 0x04 0x00 0x45 0x04 0x00 0x4b 0x04>;
				#stream-id-cells = <0x01>;
				iommus = <0x28 0x860>;
				snps,quirk-frame-length-adjustment = <0x20>;
				snps,refclk_fladj;
				snps,enable_guctl1_resume_quirk;
				snps,enable_guctl1_ipd_quirk;
				snps,xhci-stream-quirk;
				dr_mode = "host";
				snps,usb3_lpm_capable;
				phy-names = "usb3-phy";
				phys = <0x37 0x04 0x00 0x02 0x18cba80>;
				maximum-speed = "super-speed";
				phandle = <0x10>;
			};
		};

		usb1@ff9e0000 {
			#address-cells = <0x02>;
			#size-cells = <0x02>;
			status = "disabled";
			compatible = "xlnx,zynqmp-dwc3";
			reg = <0x00 0xff9e0000 0x00 0x100>;
			clock-names = "bus_clk\0ref_clk";
			power-domains = <0x26 0x17>;
			ranges;
			nvmem-cells = <0x30>;
			nvmem-cell-names = "soc_revision";
			clocks = <0x03 0x21 0x03 0x22>;

			dwc3@fe300000 {
				compatible = "snps,dwc3";
				status = "disabled";
				reg = <0x00 0xfe300000 0x00 0x40000>;
				interrupt-parent = <0x04>;
				interrupt-names = "dwc_usb3\0otg\0hiber";
				interrupts = <0x00 0x46 0x04 0x00 0x4a 0x04 0x00 0x4c 0x04>;
				#stream-id-cells = <0x01>;
				iommus = <0x28 0x861>;
				snps,quirk-frame-length-adjustment = <0x20>;
				snps,refclk_fladj;
				snps,enable_guctl1_resume_quirk;
				snps,enable_guctl1_ipd_quirk;
				snps,xhci-stream-quirk;
				phandle = <0x11>;
			};
		};

		watchdog@fd4d0000 {
			compatible = "cdns,wdt-r1p2";
			status = "okay";
			interrupt-parent = <0x04>;
			interrupts = <0x00 0x71 0x01>;
			reg = <0x00 0xfd4d0000 0x00 0x1000>;
			timeout-sec = <0x3c>;
			reset-on-timeout;
			clocks = <0x03 0x4b>;
		};

		watchdog@ff150000 {
			compatible = "cdns,wdt-r1p2";
			status = "okay";
			interrupt-parent = <0x04>;
			interrupts = <0x00 0x34 0x01>;
			reg = <0x00 0xff150000 0x00 0x1000>;
			timeout-sec = <0x0a>;
			clocks = <0x03 0x70>;
		};

		ams@ffa50000 {
			compatible = "xlnx,zynqmp-ams";
			status = "okay";
			interrupt-parent = <0x04>;
			interrupts = <0x00 0x38 0x04>;
			interrupt-names = "ams-irq";
			reg = <0x00 0xffa50000 0x00 0x800>;
			reg-names = "ams-base";
			#address-cells = <0x02>;
			#size-cells = <0x02>;
			#io-channel-cells = <0x01>;
			ranges;
			clocks = <0x03 0x46>;

			ams_ps@ffa50800 {
				compatible = "xlnx,zynqmp-ams-ps";
				status = "okay";
				reg = <0x00 0xffa50800 0x00 0x400>;
			};

			ams_pl@ffa50c00 {
				compatible = "xlnx,zynqmp-ams-pl";
				status = "okay";
				reg = <0x00 0xffa50c00 0x00 0x400>;
			};
		};

		dma@fd4c0000 {
			compatible = "xlnx,dpdma";
			status = "okay";
			reg = <0x00 0xfd4c0000 0x00 0x1000>;
			interrupts = <0x00 0x7a 0x04>;
			interrupt-parent = <0x04>;
			clock-names = "axi_clk";
			power-domains = <0x26 0x29>;
			dma-channels = <0x06>;
			#dma-cells = <0x01>;
			clocks = <0x03 0x14>;
			phandle = <0x3b>;

			dma-video0channel {
				compatible = "xlnx,video0";
			};

			dma-video1channel {
				compatible = "xlnx,video1";
			};

			dma-video2channel {
				compatible = "xlnx,video2";
			};

			dma-graphicschannel {
				compatible = "xlnx,graphics";
			};

			dma-audio0channel {
				compatible = "xlnx,audio0";
			};

			dma-audio1channel {
				compatible = "xlnx,audio1";
			};
		};

		zynqmp-display@fd4a0000 {
			compatible = "xlnx,zynqmp-dpsub-1.7";
			status = "okay";
			reg = <0x00 0xfd4a0000 0x00 0x1000 0x00 0xfd4aa000 0x00 0x1000 0x00 0xfd4ab000 0x00 0x1000 0x00 0xfd4ac000 0x00 0x1000>;
			reg-names = "dp\0blend\0av_buf\0aud";
			interrupts = <0x00 0x77 0x04>;
			interrupt-parent = <0x04>;
			clock-names = "dp_apb_clk\0dp_aud_clk\0dp_vtc_pixel_clk_in";
			power-domains = <0x26 0x29>;
			clocks = <0x38 0x03 0x11 0x03 0x10>;
			phy-names = "dp-phy0\0dp-phy1";
			phys = <0x39 0x06 0x00 0x03 0x19bfcc0 0x3a 0x06 0x01 0x03 0x19bfcc0>;
			xlnx,max-lanes = <0x02>;

			vid-layer {
				dma-names = "vid0\0vid1\0vid2";
				dmas = <0x3b 0x00 0x3b 0x01 0x3b 0x02>;
			};

			gfx-layer {
				dma-names = "gfx0";
				dmas = <0x3b 0x03>;
			};

			i2c-bus {
			};

			zynqmp_dp_snd_codec0 {
				compatible = "xlnx,dp-snd-codec";
				clock-names = "aud_clk";
				clocks = <0x03 0x11>;
				status = "okay";
				phandle = <0x3e>;
			};

			zynqmp_dp_snd_pcm0 {
				compatible = "xlnx,dp-snd-pcm";
				dmas = <0x3b 0x04>;
				dma-names = "tx";
				status = "okay";
				phandle = <0x3c>;
			};

			zynqmp_dp_snd_pcm1 {
				compatible = "xlnx,dp-snd-pcm";
				dmas = <0x3b 0x05>;
				dma-names = "tx";
				status = "okay";
				phandle = <0x3d>;
			};

			zynqmp_dp_snd_card {
				compatible = "xlnx,dp-snd-card";
				xlnx,dp-snd-pcm = <0x3c 0x3d>;
				xlnx,dp-snd-codec = <0x3e>;
				status = "okay";
			};
		};
	};

	fclk0 {
		status = "okay";
		compatible = "xlnx,fclk";
		clocks = <0x03 0x47>;
	};

	fclk1 {
		status = "okay";
		compatible = "xlnx,fclk";
		clocks = <0x03 0x48>;
	};

	fclk2 {
		status = "okay";
		compatible = "xlnx,fclk";
		clocks = <0x03 0x49>;
	};

	fclk3 {
		status = "okay";
		compatible = "xlnx,fclk";
		clocks = <0x03 0x4a>;
	};

	pss_ref_clk {
		u-boot,dm-pre-reloc;
		compatible = "fixed-clock";
		#clock-cells = <0x00>;
		clock-frequency = <0x1fca055>;
		phandle = <0x06>;
	};

	video_clk {
		u-boot,dm-pre-reloc;
		compatible = "fixed-clock";
		#clock-cells = <0x00>;
		clock-frequency = <0x19bfcc0>;
		phandle = <0x07>;
	};

	pss_alt_ref_clk {
		u-boot,dm-pre-reloc;
		compatible = "fixed-clock";
		#clock-cells = <0x00>;
		clock-frequency = <0x00>;
		phandle = <0x08>;
	};

	gt_crx_ref_clk {
		u-boot,dm-pre-reloc;
		compatible = "fixed-clock";
		#clock-cells = <0x00>;
		clock-frequency = <0x66ff300>;
		phandle = <0x0a>;
	};

	aux_ref_clk {
		u-boot,dm-pre-reloc;
		compatible = "fixed-clock";
		#clock-cells = <0x00>;
		clock-frequency = <0x19bfcc0>;
		phandle = <0x09>;
	};

	dp_aclk {
		compatible = "fixed-clock";
		#clock-cells = <0x00>;
		clock-frequency = <0x5f5e100>;
		clock-accuracy = <0x64>;
		phandle = <0x38>;
	};
	
	ina226 {
		compatible = "iio-hwmon";
		io-channels = <0x3f 0x00 0x3f 0x01 0x3f 0x02 0x3f 0x03>;
	};

	amba_pl@0 {
		#address-cells = <0x02>;
		#size-cells = <0x02>;
		compatible = "simple-bus";
		ranges;

		v_frmbuf_rd@a0000000 {
			#dma-cells = <0x01>;
			clock-names = "ap_clk";
			clocks = <0x40>;
			compatible = "xlnx,v-frmbuf-rd-2.1\0xlnx,axi-frmbuf-rd-v2.1";
			interrupt-names = "interrupt";
			interrupt-parent = <0x04>;
			interrupts = <0x00 0x5a 0x04>;
			reg = <0x00 0xa0000000 0x00 0x10000>;
			xlnx,dma-addr-width = <0x40>;
			xlnx,dma-align = <0x10>;
			xlnx,max-height = <0x870>;
			xlnx,max-width = <0xf00>;
			xlnx,pixels-per-clock = <0x02>;
			xlnx,s-axi-ctrl-addr-width = <0x07>;
			xlnx,s-axi-ctrl-data-width = <0x20>;
			xlnx,vid-formats = "y8\0y10\0nv12\0nv16\0xv20\0xv15";
			xlnx,video-width = <0x0a>;
		};

		misc_clk_0 {
			#clock-cells = <0x00>;
			clock-frequency = <0x13b3e0a3>;
			compatible = "fixed-clock";
			phandle = <0x40>;
		};

		v_frmbuf_wr@a0010000 {
			#dma-cells = <0x01>;
			clock-names = "ap_clk";
			clocks = <0x40>;
			compatible = "xlnx,v-frmbuf-wr-2.1\0xlnx,axi-frmbuf-wr-v2.1";
			interrupt-names = "interrupt";
			interrupt-parent = <0x04>;
			interrupts = <0x00 0x5b 0x04>;
			reg = <0x00 0xa0010000 0x00 0x10000>;
			xlnx,dma-addr-width = <0x20>;
			xlnx,dma-align = <0x10>;
			xlnx,max-height = <0x870>;
			xlnx,max-width = <0xf00>;
			xlnx,pixels-per-clock = <0x02>;
			xlnx,s-axi-ctrl-addr-width = <0x07>;
			xlnx,s-axi-ctrl-data-width = <0x20>;
			xlnx,vid-formats = "y8\0y10\0nv12\0nv16\0xv20\0xv15";
			xlnx,video-width = <0x0a>;
		};

		vcu@a0100000 {
			#address-cells = <0x02>;
			#clock-cells = <0x01>;
			#size-cells = <0x02>;
			clock-names = "pll_ref\0aclk\0vcu_core_enc\0vcu_core_dec\0vcu_mcu_enc\0vcu_mcu_dec";
			clocks = <0x41 0x42 0x43 0x01 0x43 0x02 0x43 0x03 0x43 0x04>;
			compatible = "xlnx,vcu-1.2\0xlnx,vcu";
			interrupt-names = "vcu_host_interrupt";
			interrupt-parent = <0x04>;
			interrupts = <0x00 0x59 0x04>;
			ranges;
			reg = <0x00 0xa0140000 0x00 0x1000 0x00 0xa0141000 0x00 0x1000>;
			reg-names = "vcu_slcr\0logicore";
			reset-gpios = <0x2d 0x4e 0x00>;
			phandle = <0x43>;

			al5e@a0100000 {
				compatible = "al,al5e-1.2\0al,al5e";
				interrupt-parent = <0x04>;
				interrupts = <0x00 0x59 0x04>;
				reg = <0x00 0xa0100000 0x00 0x10000>;
			};

			al5d@a0120000 {
				compatible = "al,al5d-1.2\0al,al5d";
				interrupt-parent = <0x04>;
				interrupts = <0x00 0x59 0x04>;
				reg = <0x00 0xa0120000 0x00 0x10000>;
			};
		};

		misc_clk_1 {
			#clock-cells = <0x00>;
			clock-frequency = <0x1fca055>;
			compatible = "fixed-clock";
			phandle = <0x41>;
		};

		misc_clk_2 {
			#clock-cells = <0x00>;
			clock-frequency = <0x5e929ca>;
			compatible = "fixed-clock";
			phandle = <0x42>;
		};

		vcu_ddr4_controller@4800000000 {
			clock-names = "S_Axi_Clk";
			clocks = <0x44>;
			compatible = "xlnx,vcu-ddr4-controller-1.1";
			reg = <0x48 0x00 0x00 0x80000000>;
			xlnx,wrpipe = <0x01>;
		};

		misc_clk_3 {
			#clock-cells = <0x00>;
			clock-frequency = <0xfda3046>;
			compatible = "fixed-clock";
			phandle = <0x44>;
		};
	};

	aliases {
		ethernet0 = "/amba/ethernet@ff0e0000";
		i2c0 = "/amba/i2c@ff030000";
		serial0 = "/amba/serial@ff000000";
		// serial1 = "/amba/serial@ff010000";
		spi0 = "/amba/spi@ff0f0000";
		mmc0 = "/amba/mmc@ff170000";
	};

	memory {
		device_type = "memory";
		reg = <0x00 0x00 0x00 0x7ff00000>;
	};

	chosen {
		bootargs = "earlycon console=ttyPS0,115200 clk_ignore_unused mem=512M root=/dev/mmcblk0p2 rw rootwait init=/root/jailhouse/scripts/boot.sh";
		stdout-path = "serial0:115200n8";
	};


};
